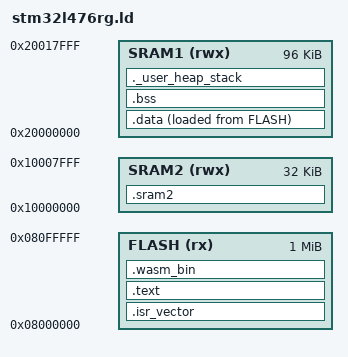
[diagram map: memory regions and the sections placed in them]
/* STM32L476RG: 1MB Flash, 96KB SRAM1 + 32KB SRAM2 */
MEMORY
{
    FLASH (rx)  : ORIGIN = 0x08000000, LENGTH = 1024K
    SRAM1 (rwx) : ORIGIN = 0x20000000, LENGTH = 96K
    SRAM2 (rwx) : ORIGIN = 0x10000000, LENGTH = 32K
}

_estack = ORIGIN(SRAM1) + LENGTH(SRAM1);

SECTIONS
{
    .isr_vector :
    {
        . = ALIGN(4);
        KEEP(*(.isr_vector))
        . = ALIGN(4);
    } > FLASH

    .text :
    {
        . = ALIGN(4);
        *(.text)
        *(.text*)
        *(.rodata)
        *(.rodata*)
        . = ALIGN(4);
        _etext = .;
    } > FLASH

    .wasm_bin :
    {
        . = ALIGN(4);
        *(.wasm_bin)
        *(.wasm_bin*)
        . = ALIGN(4);
    } > FLASH

    _sidata = LOADADDR(.data);

    .data :
    {
        . = ALIGN(4);
        _sdata = .;
        *(.data)
        *(.data*)
        . = ALIGN(4);
        _edata = .;
    } > SRAM1 AT> FLASH

    .bss :
    {
        . = ALIGN(4);
        _sbss = .;
        __bss_start__ = _sbss;
        *(.bss)
        *(.bss*)
        *(COMMON)
        . = ALIGN(4);
        _ebss = .;
        __bss_end__ = _ebss;
    } > SRAM1

    .sram2 (NOLOAD) :
    {
        . = ALIGN(4);
        *(.sram2)
        *(.sram2*)
        . = ALIGN(4);
    } > SRAM2

    ._user_heap_stack :
    {
        . = ALIGN(8);
        PROVIDE(end = .);
        PROVIDE(_end = .);
        . = . + 0x10000;  /* 64KB min heap for wasm linear memory via malloc */
        . = . + 0x1000;   /* 4KB min stack */
        . = ALIGN(8);
    } > SRAM1

    /DISCARD/ :
    {
        *(.ARM.attributes)
    }
}
